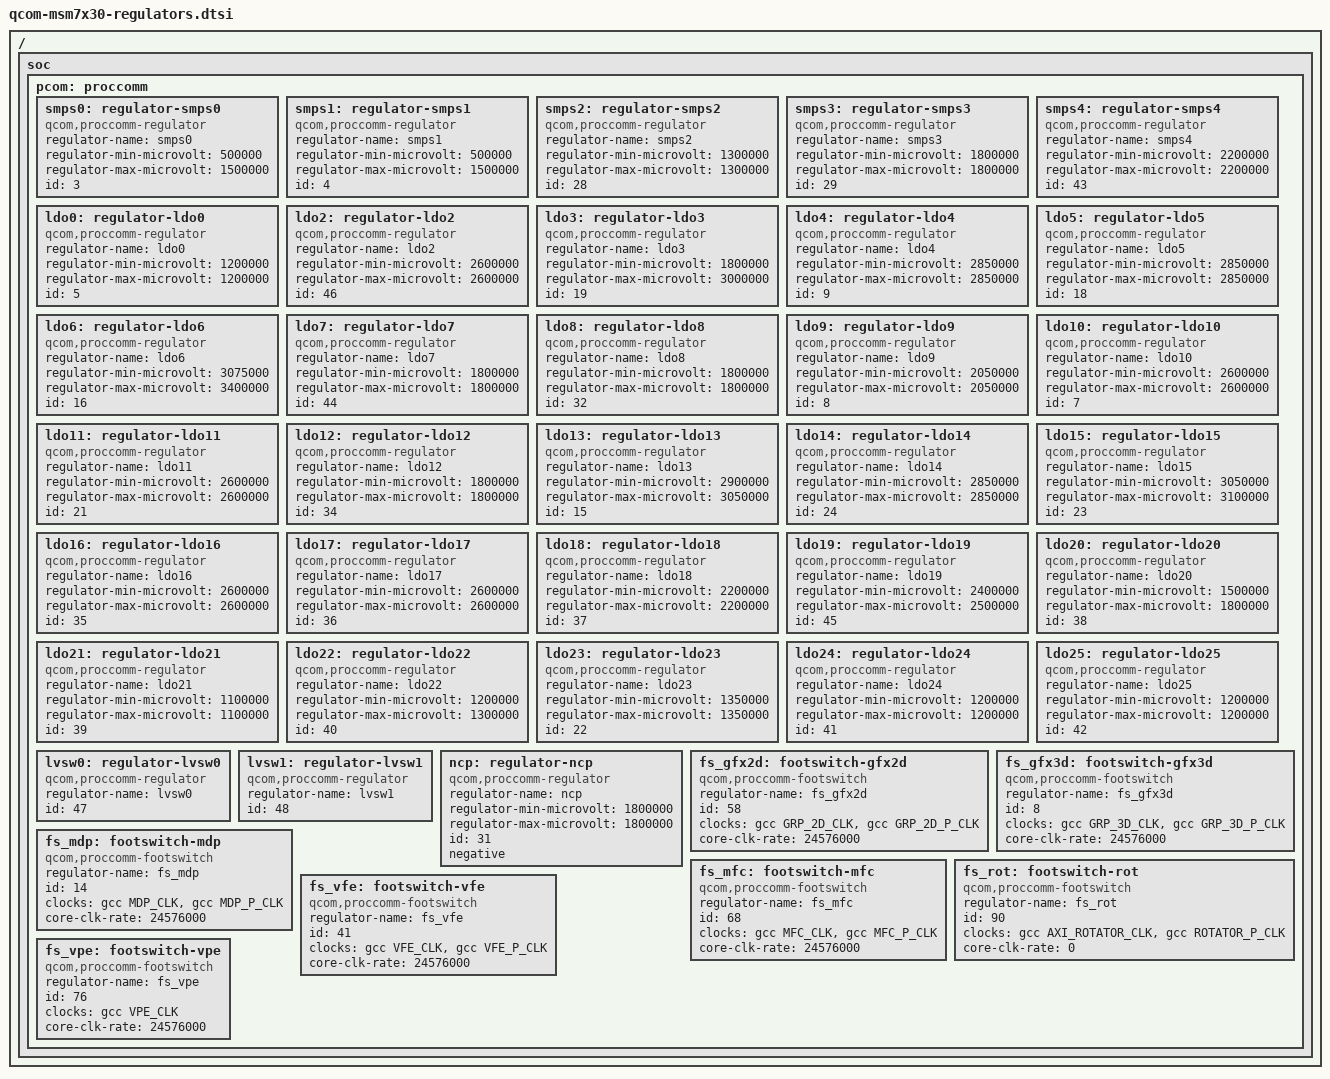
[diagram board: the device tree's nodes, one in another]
#include <dt-bindings/clock/qcom,gcc-msm7x30.h>

/ {
	soc: soc {
		pcom: proccomm {
			smps0: regulator-smps0 {
				compatible = "qcom,proccomm-regulator";
				regulator-name = "smps0";
				regulator-min-microvolt = <500000>;
				regulator-max-microvolt = <1500000>;
				id = <3>;
			};

			smps1: regulator-smps1 {
				compatible = "qcom,proccomm-regulator";
				regulator-name = "smps1";
				regulator-min-microvolt = <500000>;
				regulator-max-microvolt = <1500000>;
				id = <4>;
			};

			smps2: regulator-smps2 {
				compatible = "qcom,proccomm-regulator";
				regulator-name = "smps2";
				regulator-min-microvolt = <1300000>;
				regulator-max-microvolt = <1300000>;
				id = <28>;
			};

			smps3: regulator-smps3 {
				compatible = "qcom,proccomm-regulator";
				regulator-name = "smps3";
				regulator-min-microvolt = <1800000>;
				regulator-max-microvolt = <1800000>;
				id = <29>;
			};

			smps4: regulator-smps4 {
				compatible = "qcom,proccomm-regulator";
				regulator-name = "smps4";
				regulator-min-microvolt = <2200000>;
				regulator-max-microvolt = <2200000>;
				id = <43>;
			};

			ldo0: regulator-ldo0 {
				compatible = "qcom,proccomm-regulator";
				regulator-name = "ldo0";
				regulator-min-microvolt = <1200000>;
				regulator-max-microvolt = <1200000>;
				id = <5>;
			};

			ldo2: regulator-ldo2 {
				compatible = "qcom,proccomm-regulator";
				regulator-name = "ldo2";
				regulator-min-microvolt = <2600000>;
				regulator-max-microvolt = <2600000>;
				id = <46>;
			};

			ldo3: regulator-ldo3 {
				compatible = "qcom,proccomm-regulator";
				regulator-name = "ldo3";
				regulator-min-microvolt = <1800000>;
				regulator-max-microvolt = <3000000>;
				id = <19>;
			};

			ldo4: regulator-ldo4 {
				compatible = "qcom,proccomm-regulator";
				regulator-name = "ldo4";
				regulator-min-microvolt = <2850000>;
				regulator-max-microvolt = <2850000>;
				id = <9>;
			};

			ldo5: regulator-ldo5 {
				compatible = "qcom,proccomm-regulator";
				regulator-name = "ldo5";
				regulator-min-microvolt = <2850000>;
				regulator-max-microvolt = <2850000>;
				id = <18>;
			};

			ldo6: regulator-ldo6 {
				compatible = "qcom,proccomm-regulator";
				regulator-name = "ldo6";
				regulator-min-microvolt = <3075000>;
				regulator-max-microvolt = <3400000>;
				id = <16>;
			};

			ldo7: regulator-ldo7 {
				compatible = "qcom,proccomm-regulator";
				regulator-name = "ldo7";
				regulator-min-microvolt = <1800000>;
				regulator-max-microvolt = <1800000>;
				id = <44>;
			};

			ldo8: regulator-ldo8 {
				compatible = "qcom,proccomm-regulator";
				regulator-name = "ldo8";
				regulator-min-microvolt = <1800000>;
				regulator-max-microvolt = <1800000>;
				id = <32>;
			};

			ldo9: regulator-ldo9 {
				compatible = "qcom,proccomm-regulator";
				regulator-name = "ldo9";
				regulator-min-microvolt = <2050000>;
				regulator-max-microvolt = <2050000>;
				id = <8>;
			};

			ldo10: regulator-ldo10 {
				compatible = "qcom,proccomm-regulator";
				regulator-name = "ldo10";
				regulator-min-microvolt = <2600000>;
				regulator-max-microvolt = <2600000>;
				id = <7>;
			};

			ldo11: regulator-ldo11 {
				compatible = "qcom,proccomm-regulator";
				regulator-name = "ldo11";
				regulator-min-microvolt = <2600000>;
				regulator-max-microvolt = <2600000>;
				id = <21>;
			};

			ldo12: regulator-ldo12 {
				compatible = "qcom,proccomm-regulator";
				regulator-name = "ldo12";
				regulator-min-microvolt = <1800000>;
				regulator-max-microvolt = <1800000>;
				id = <34>;
			};

			ldo13: regulator-ldo13 {
				compatible = "qcom,proccomm-regulator";
				regulator-name = "ldo13";
				regulator-min-microvolt = <2900000>;
				regulator-max-microvolt = <3050000>;
				id = <15>;
			};

			ldo14: regulator-ldo14 {
				compatible = "qcom,proccomm-regulator";
				regulator-name = "ldo14";
				regulator-min-microvolt = <2850000>;
				regulator-max-microvolt = <2850000>;
				id = <24>;
			};

			ldo15: regulator-ldo15 {
				compatible = "qcom,proccomm-regulator";
				regulator-name = "ldo15";
				regulator-min-microvolt = <3050000>;
				regulator-max-microvolt = <3100000>;
				id = <23>;
			};

			ldo16: regulator-ldo16 {
				compatible = "qcom,proccomm-regulator";
				regulator-name = "ldo16";
				regulator-min-microvolt = <2600000>;
				regulator-max-microvolt = <2600000>;
				id = <35>;
			};

			ldo17: regulator-ldo17 {
				compatible = "qcom,proccomm-regulator";
				regulator-name = "ldo17";
				regulator-min-microvolt = <2600000>;
				regulator-max-microvolt = <2600000>;
				id = <36>;
			};

			ldo18: regulator-ldo18 {
				compatible = "qcom,proccomm-regulator";
				regulator-name = "ldo18";
				regulator-min-microvolt = <2200000>;
				regulator-max-microvolt = <2200000>;
				id = <37>;
			};

			ldo19: regulator-ldo19 {
				compatible = "qcom,proccomm-regulator";
				regulator-name = "ldo19";
				regulator-min-microvolt = <2400000>;
				regulator-max-microvolt = <2500000>;
				id = <45>;
			};

			ldo20: regulator-ldo20 {
				compatible = "qcom,proccomm-regulator";
				regulator-name = "ldo20";
				regulator-min-microvolt = <1500000>;
				regulator-max-microvolt = <1800000>;
				id = <38>;
			};

			ldo21: regulator-ldo21 {
				compatible = "qcom,proccomm-regulator";
				regulator-name = "ldo21";
				regulator-min-microvolt = <1100000>;
				regulator-max-microvolt = <1100000>;
				id = <39>;
			};

			ldo22: regulator-ldo22 {
				compatible = "qcom,proccomm-regulator";
				regulator-name = "ldo22";
				regulator-min-microvolt = <1200000>;
				regulator-max-microvolt = <1300000>;
				id = <40>;
			};

			ldo23: regulator-ldo23 {
				compatible = "qcom,proccomm-regulator";
				regulator-name = "ldo23";
				regulator-min-microvolt = <1350000>;
				regulator-max-microvolt = <1350000>;
				id = <22>;
			};

			ldo24: regulator-ldo24 {
				compatible = "qcom,proccomm-regulator";
				regulator-name = "ldo24";
				regulator-min-microvolt = <1200000>;
				regulator-max-microvolt = <1200000>;
				id = <41>;
			};

			ldo25: regulator-ldo25 {
				compatible = "qcom,proccomm-regulator";
				regulator-name = "ldo25";
				regulator-min-microvolt = <1200000>;
				regulator-max-microvolt = <1200000>;
				id = <42>;
			};

			lvsw0: regulator-lvsw0 {
				compatible = "qcom,proccomm-regulator";
				regulator-name = "lvsw0";
				id = <47>;
			};

			lvsw1: regulator-lvsw1 {
				compatible = "qcom,proccomm-regulator";
				regulator-name = "lvsw1";
				id = <48>;
			};

			ncp: regulator-ncp {
				compatible = "qcom,proccomm-regulator";
				regulator-name = "ncp";
				regulator-min-microvolt = <1800000>;
				regulator-max-microvolt = <1800000>;
				id = <31>;
				negative;
			};

			fs_gfx2d:footswitch-gfx2d {
				compatible = "qcom,proccomm-footswitch";
				regulator-name = "fs_gfx2d";

				id = <58>;
				clocks = <&gcc GRP_2D_CLK>, <&gcc GRP_2D_P_CLK>;
				clock-names = "core", "iface";
				core-clk-rate = <24576000>;
			};

			fs_gfx3d:footswitch-gfx3d {
				compatible = "qcom,proccomm-footswitch";
				regulator-name = "fs_gfx3d";

				id = <8>;
				clocks = <&gcc GRP_3D_CLK>, <&gcc GRP_3D_P_CLK>;
				clock-names = "core", "iface";
				core-clk-rate = <24576000>;
			};

			fs_mdp:footswitch-mdp {
				compatible = "qcom,proccomm-footswitch";
				regulator-name = "fs_mdp";

				id = <14>;
				clocks = <&gcc MDP_CLK>, <&gcc MDP_P_CLK>;
				clock-names = "core", "iface";
				core-clk-rate = <24576000>;
			};

			fs_mfc:footswitch-mfc {
				compatible = "qcom,proccomm-footswitch";
				regulator-name = "fs_mfc";

				id = <68>;
				clocks = <&gcc MFC_CLK>, <&gcc MFC_P_CLK>;
				clock-names = "core", "iface";
				core-clk-rate = <24576000>;
			};

			fs_rot:footswitch-rot {
				compatible = "qcom,proccomm-footswitch";
				regulator-name = "fs_rot";

				id = <90>;
				clocks = <&gcc AXI_ROTATOR_CLK>, <&gcc ROTATOR_P_CLK>;
				clock-names = "core", "iface";
				core-clk-rate = <0>;
			};

			fs_vfe:footswitch-vfe {
				compatible = "qcom,proccomm-footswitch";
				regulator-name = "fs_vfe";

				id = <41>;
				clocks = <&gcc VFE_CLK>, <&gcc VFE_P_CLK>;
				clock-names = "core", "iface";
				core-clk-rate = <24576000>;
			};

			fs_vpe:footswitch-vpe {
				compatible = "qcom,proccomm-footswitch";
				regulator-name = "fs_vpe";

				id = <76>;
				clocks = <&gcc VPE_CLK>;
				clock-names = "core";
				core-clk-rate = <24576000>;
			};
		};
	};
};
